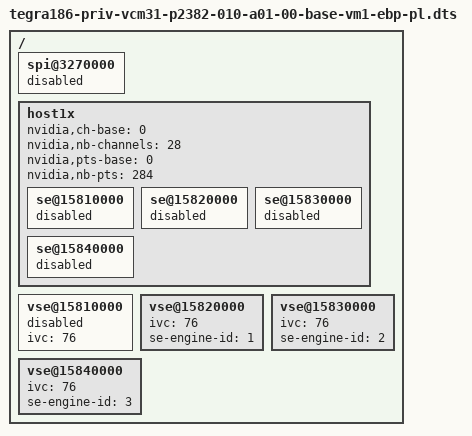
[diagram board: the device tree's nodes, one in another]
/*
 * tegra186-priv-vcm31-p2382-010-a01-00-base-vm1-ebp-pl.dts: P2382(sunstreaker) base vm1 dts
 * file
 *
 * Copyright (c) 2016, NVIDIA CORPORATION.  All rights reserved.
 *
 * This program is free software; you can redistribute it and/or modify
 * it under the terms of the GNU General Public License as published by
 * the Free Software Foundation; version 2 of the License.
 *
 * This program is distributed in the hope that it will be useful, but WITHOUT
 * ANY WARRANTY; without even the implied warranty of MERCHANTABILITY or
 * FITNESS FOR A PARTICULAR PURPOSE.  See the GNU General Public License for
 * more details.
 */

#include "tegra186-priv-vcm31-p2382-010-a01-00-base-vm1-ebp.dts"

/ {
	spi@3270000 {
		status = "disabled";
	};

	host1x: host1x {
		nvidia,ch-base = <0>;
		nvidia,nb-channels = <28>;
		nvidia,pts-base = <0>;
		nvidia,nb-pts = <284>;

		se@15810000 {
			status = "disabled";
		};

		se@15820000 {
			status = "disabled";
		};

		se@15830000 {
			status = "disabled";
		};

		se@15840000 {
			status = "disabled";
		};
	};

	vse@15810000 {
		ivc = <76>;
		status = "disabled";
	};

	vse@15820000 {
		ivc = <76>;
		se-engine-id = <1>;
	};

	vse@15830000 {
		ivc = <76>;
		se-engine-id = <2>;
	};

	vse@15840000 {
		ivc = <76>;
		se-engine-id = <3>;
	};
};
